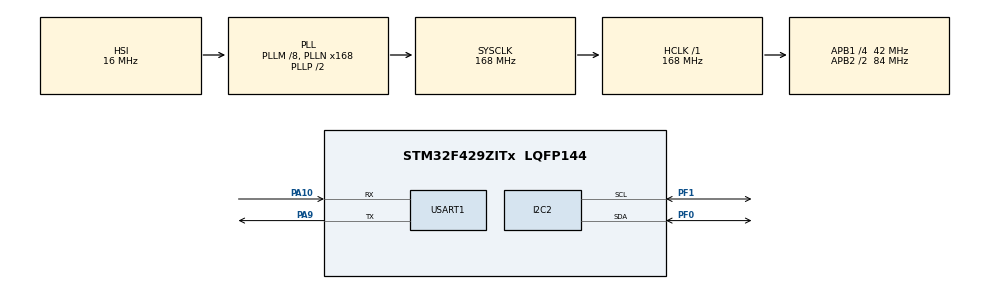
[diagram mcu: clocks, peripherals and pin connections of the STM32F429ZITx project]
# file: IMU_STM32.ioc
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Mcu.Family=STM32F4
RCC.CortexFreq_Value=168000000
PA10.Mode=Asynchronous
RCC.APB1CLKDivider=RCC_HCLK_DIV4
RCC.SYSCLKSource=RCC_SYSCLKSOURCE_PLLCLK
ProjectManager.StackSize=0x400
PA13.Signal=SYS_JTMS-SWDIO
PF1.Mode=I2C
PA9.Mode=Asynchronous
ProjectManager.TargetToolchain=STM32CubeIDE
PH0/OSC_IN.Mode=HSE-External-Clock-Source
RCC.HCLKFreq_Value=168000000
RCC.APB2TimFreq_Value=168000000
PA9.Signal=USART1_TX
PH1/OSC_OUT.Signal=RCC_OSC_OUT
RCC.LSE_VALUE=32768
RCC.AHBFreq_Value=168000000
RCC.HSE_VALUE=8000000
PB3.Mode=Trace_Asynchronous_SW
board=STM32F429I-DISC1
RCC.VCOOutputFreq_Value=336000000
PH0/OSC_IN.Signal=RCC_OSC_IN
RCC.APB2Freq_Value=84000000
PA14.Mode=Trace_Asynchronous_SW
PF1.Signal=I2C2_SCL
PA13.Mode=Trace_Asynchronous_SW
PH1/OSC_OUT.Mode=HSE-External-Clock-Source
Mcu.Name=STM32F429ZITx
RCC.48MHZClocksFreq_Value=48000000
PB3.Signal=SYS_JTDO-SWO
RCC.SYSCLKFreq_VALUE=168000000
Mcu.Package=LQFP144
USART1.VirtualMode=VM_ASYNC
PA10.Signal=USART1_RX
PA14.Signal=SYS_JTCK-SWCLK
ProjectManager.HeapSize=0x200
PF0.Mode=I2C
RCC.HSI_VALUE=16000000
RCC.PLLQ=7
NVIC.PriorityGroup=NVIC_PRIORITYGROUP_0
RCC.APB2CLKDivider=RCC_HCLK_DIV2
RCC.PLLM=8
RCC.PLLN=168
RCC.APB1TimFreq_Value=84000000
PF0.Signal=I2C2_SDA
RCC.APB1Freq_Value=42000000
I2C2.I2C_Mode=I2C_Standard

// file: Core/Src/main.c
/* USER CODE BEGIN Header */
/**
  ******************************************************************************
  * @file           : main.c
  * @brief          : Main program body
  ******************************************************************************
  * @attention
  *
  * <h2><center>&copy; Copyright (c) 2021 STMicroelectronics.
  * All rights reserved.</center></h2>
  *
  * This software component is licensed by ST under BSD 3-Clause license,
  * the "License"; You may not use this file except in compliance with the
  * License. You may obtain a copy of the License at:
  *                        opensource.org/licenses/BSD-3-Clause
  *
  ******************************************************************************
  */
/* USER CODE END Header */
#include "main.h"

/* USER CODE BEGIN Includes */
#include "MPU6050.h"
#include <stdio.h>
#include "retarget.h"
/* USER CODE END Includes */

I2C_HandleTypeDef hi2c2;

UART_HandleTypeDef huart1;

/* USER CODE BEGIN PV */

// mpu6050 configuration array
uint8_t arr_cong[8] = {MPU6050_SMPLRT_DIV_R,0x07, MPU6050_PWR_MGMT_1_R,0x01, MPU6050_GYRO_CONFIG_R,0,MPU6050_ACCEL_CONFIG_R,0x18};

MPU6050_ANGELS_t ANGELS_VAR_STRUCT;

/* USER CODE END PV */

void SystemClock_Config(void);
static void MX_GPIO_Init(void);
static void MX_I2C2_Init(void);
static void MX_USART1_UART_Init(void);

int main(void)
{

  /* MCU Configuration--------------------------------------------------------*/

  /* Reset of all peripherals, Initializes the Flash interface and the Systick. */
  HAL_Init();

  /* Configure the system clock */
  SystemClock_Config();

  /* Initialize all configured peripherals */
  MX_GPIO_Init();
  MX_I2C2_Init();
  MX_USART1_UART_Init();
  /* USER CODE BEGIN 2 */
  HAL_Delay(300);
  MPU6050_SET_Config(arr_cong ,sizeof(arr_cong));
  /* USER CODE END 2 */
  RetargetInit(&huart1);
  /* Infinite loop */
  while (1)
  {

    /* USER CODE BEGIN 3 */
	  Read_Accurate_Angles_ComplemantrayFilter(&ANGELS_VAR_STRUCT);
	  HAL_Delay(4);
	  printf("pitch = %0.2f  ,  Roll = %0.2f  , Yaw = %0.2f  \n",ANGELS_VAR_STRUCT.GYRO_ANGLE_PITCH
			  	  	  	  	  	  	  	  	  	  	  ,ANGELS_VAR_STRUCT.GYRO_ANGLE_ROLL
													  ,ANGELS_VAR_STRUCT.GYRO_ANGLE_YAW);
  }
  /* USER CODE END 3 */
}

void SystemClock_Config(void)
{
  RCC_OscInitTypeDef RCC_OscInitStruct = {0};
  RCC_ClkInitTypeDef RCC_ClkInitStruct = {0};

  /** Configure the main internal regulator output voltage
  */
  __HAL_RCC_PWR_CLK_ENABLE();
  __HAL_PWR_VOLTAGESCALING_CONFIG(PWR_REGULATOR_VOLTAGE_SCALE1);
  /** Initializes the RCC Oscillators according to the specified parameters
  * in the RCC_OscInitTypeDef structure.
  */
  RCC_OscInitStruct.OscillatorType = RCC_OSCILLATORTYPE_HSI;
  RCC_OscInitStruct.HSIState = RCC_HSI_ON;
  RCC_OscInitStruct.HSICalibrationValue = RCC_HSICALIBRATION_DEFAULT;
  RCC_OscInitStruct.PLL.PLLState = RCC_PLL_ON;
  RCC_OscInitStruct.PLL.PLLSource = RCC_PLLSOURCE_HSI;
  RCC_OscInitStruct.PLL.PLLM = 8;
  RCC_OscInitStruct.PLL.PLLN = 168;
  RCC_OscInitStruct.PLL.PLLP = RCC_PLLP_DIV2;
  RCC_OscInitStruct.PLL.PLLQ = 7;
  if (HAL_RCC_OscConfig(&RCC_OscInitStruct) != HAL_OK)
  {
    Error_Handler();
  }
  /** Initializes the CPU, AHB and APB buses clocks
  */
  RCC_ClkInitStruct.ClockType = RCC_CLOCKTYPE_HCLK|RCC_CLOCKTYPE_SYSCLK
                              |RCC_CLOCKTYPE_PCLK1|RCC_CLOCKTYPE_PCLK2;
  RCC_ClkInitStruct.SYSCLKSource = RCC_SYSCLKSOURCE_PLLCLK;
  RCC_ClkInitStruct.AHBCLKDivider = RCC_SYSCLK_DIV1;
  RCC_ClkInitStruct.APB1CLKDivider = RCC_HCLK_DIV4;
  RCC_ClkInitStruct.APB2CLKDivider = RCC_HCLK_DIV2;

  if (HAL_RCC_ClockConfig(&RCC_ClkInitStruct, FLASH_LATENCY_5) != HAL_OK)
  {
    Error_Handler();
  }
}

static void MX_I2C2_Init(void)
{

  hi2c2.Instance = I2C2;
  hi2c2.Init.ClockSpeed = 100000;
  hi2c2.Init.DutyCycle = I2C_DUTYCYCLE_2;
  hi2c2.Init.OwnAddress1 = 0;
  hi2c2.Init.AddressingMode = I2C_ADDRESSINGMODE_7BIT;
  hi2c2.Init.DualAddressMode = I2C_DUALADDRESS_DISABLE;
  hi2c2.Init.OwnAddress2 = 0;
  hi2c2.Init.GeneralCallMode = I2C_GENERALCALL_DISABLE;
  hi2c2.Init.NoStretchMode = I2C_NOSTRETCH_DISABLE;
  if (HAL_I2C_Init(&hi2c2) != HAL_OK)
  {
    Error_Handler();
  }
  /** Configure Analogue filter
  */
  if (HAL_I2CEx_ConfigAnalogFilter(&hi2c2, I2C_ANALOGFILTER_ENABLE) != HAL_OK)
  {
    Error_Handler();
  }
  /** Configure Digital filter
  */
  if (HAL_I2CEx_ConfigDigitalFilter(&hi2c2, 0) != HAL_OK)
  {
    Error_Handler();
  }

}

static void MX_USART1_UART_Init(void)
{

  huart1.Instance = USART1;
  huart1.Init.BaudRate = 115200;
  huart1.Init.WordLength = UART_WORDLENGTH_8B;
  huart1.Init.StopBits = UART_STOPBITS_1;
  huart1.Init.Parity = UART_PARITY_NONE;
  huart1.Init.Mode = UART_MODE_TX_RX;
  huart1.Init.HwFlowCtl = UART_HWCONTROL_NONE;
  huart1.Init.OverSampling = UART_OVERSAMPLING_16;
  if (HAL_UART_Init(&huart1) != HAL_OK)
  {
    Error_Handler();
  }

}

static void MX_GPIO_Init(void)
{

  /* GPIO Ports Clock Enable */
  __HAL_RCC_GPIOF_CLK_ENABLE();
  __HAL_RCC_GPIOH_CLK_ENABLE();
  __HAL_RCC_GPIOA_CLK_ENABLE();
  __HAL_RCC_GPIOB_CLK_ENABLE();

}

void Error_Handler(void)
{
  __disable_irq();
  while (1)
  {
  }
}

/************************ (C) COPYRIGHT STMicroelectronics *****END OF FILE****/
